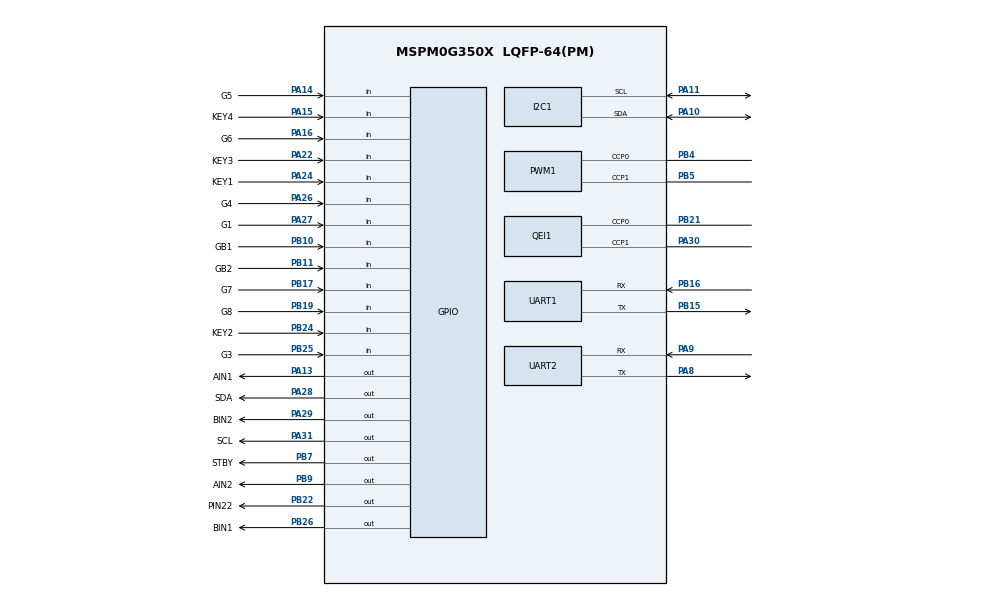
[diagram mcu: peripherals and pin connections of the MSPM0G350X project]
/**
 * @cliArgs --device "MSPM0G350X" --part "Default" --package "LQFP-64(PM)" --product "mspm0_sdk@2.10.00.04"
 * @versions {"tool":"1.26.2+4477"}
 */

/**
 * Import the modules used in this configuration.
 */
const GPIO    = scripting.addModule("/ti/driverlib/GPIO", {}, false);
const GPIO1   = GPIO.addInstance();
const GPIO2   = GPIO.addInstance();
const GPIO3   = GPIO.addInstance();
const GPIO4   = GPIO.addInstance();
const GPIO5   = GPIO.addInstance();
const I2C     = scripting.addModule("/ti/driverlib/I2C", {}, false);
const I2C1    = I2C.addInstance();
const PWM     = scripting.addModule("/ti/driverlib/PWM", {}, false);
const PWM1    = PWM.addInstance();
const QEI     = scripting.addModule("/ti/driverlib/QEI", {}, false);
const QEI1    = QEI.addInstance();
const SYSCTL  = scripting.addModule("/ti/driverlib/SYSCTL");
const SYSTICK = scripting.addModule("/ti/driverlib/SYSTICK");
const TIMER   = scripting.addModule("/ti/driverlib/TIMER", {}, false);
const TIMER1  = TIMER.addInstance();
const TIMER2  = TIMER.addInstance();
const TIMER3  = TIMER.addInstance();
const TIMER4  = TIMER.addInstance();
const UART    = scripting.addModule("/ti/driverlib/UART", {}, false);
const UART1   = UART.addInstance();
const UART2   = UART.addInstance();

/**
 * Write custom configuration values to the imported modules.
 */
GPIO1.$name                               = "Motor";
GPIO1.associatedPins.create(7);
GPIO1.associatedPins[0].$name             = "AIN1";
GPIO1.associatedPins[0].assignedPin       = "13";
GPIO1.associatedPins[0].pin.$assign       = "PA13";
GPIO1.associatedPins[1].$name             = "AIN2";
GPIO1.associatedPins[1].assignedPin       = "9";
GPIO1.associatedPins[1].pin.$assign       = "PB9";
GPIO1.associatedPins[2].$name             = "BIN1";
GPIO1.associatedPins[2].assignedPin       = "26";
GPIO1.associatedPins[2].pin.$assign       = "PB26";
GPIO1.associatedPins[3].$name             = "BIN2";
GPIO1.associatedPins[3].assignedPin       = "29";
GPIO1.associatedPins[3].pin.$assign       = "PA29";
GPIO1.associatedPins[4].$name             = "STBY";
GPIO1.associatedPins[4].assignedPin       = "07";
GPIO1.associatedPins[4].pin.$assign       = "PB7";
GPIO1.associatedPins[5].$name             = "GB1";
GPIO1.associatedPins[5].direction         = "INPUT";
GPIO1.associatedPins[5].internalResistor  = "PULL_DOWN";
GPIO1.associatedPins[5].assignedPin       = "10";
GPIO1.associatedPins[5].interruptEn       = true;
GPIO1.associatedPins[5].interruptPriority = "1";
GPIO1.associatedPins[5].pubChanID         = 1;
GPIO1.associatedPins[5].polarity          = "RISE";
GPIO1.associatedPins[5].pin.$assign       = "PB10";
GPIO1.associatedPins[6].$name             = "GB2";
GPIO1.associatedPins[6].direction         = "INPUT";
GPIO1.associatedPins[6].inputFilter       = "1_CYCLE";
GPIO1.associatedPins[6].assignedPin       = "11";
GPIO1.associatedPins[6].internalResistor  = "PULL_UP";
GPIO1.associatedPins[6].pin.$assign       = "PB11";

const Board = scripting.addModule("/ti/driverlib/Board", {}, false);

GPIO2.$name                         = "LED";
GPIO2.associatedPins[0].$name       = "PIN22";
GPIO2.associatedPins[0].assignedPin = "22";
GPIO2.associatedPins[0].pin.$assign = "PB22";

GPIO3.$name                              = "KEY";
GPIO3.associatedPins.create(4);
GPIO3.associatedPins[0].direction        = "INPUT";
GPIO3.associatedPins[0].$name            = "KEY1";
GPIO3.associatedPins[0].internalResistor = "PULL_UP";
GPIO3.associatedPins[0].assignedPin      = "24";
GPIO3.associatedPins[0].pin.$assign      = "PA24";
GPIO3.associatedPins[1].$name            = "KEY2";
GPIO3.associatedPins[1].direction        = "INPUT";
GPIO3.associatedPins[1].internalResistor = "PULL_UP";
GPIO3.associatedPins[1].assignedPin      = "24";
GPIO3.associatedPins[1].pin.$assign      = "PB24";
GPIO3.associatedPins[2].$name            = "KEY3";
GPIO3.associatedPins[2].direction        = "INPUT";
GPIO3.associatedPins[2].internalResistor = "PULL_UP";
GPIO3.associatedPins[2].assignedPin      = "22";
GPIO3.associatedPins[2].pin.$assign      = "PA22";
GPIO3.associatedPins[3].$name            = "KEY4";
GPIO3.associatedPins[3].direction        = "INPUT";
GPIO3.associatedPins[3].internalResistor = "PULL_UP";
GPIO3.associatedPins[3].assignedPin      = "15";
GPIO3.associatedPins[3].pin.$assign      = "PA15";

GPIO4.$name                         = "XG";
GPIO4.associatedPins.create(8);
GPIO4.associatedPins[0].direction   = "INPUT";
GPIO4.associatedPins[0].$name       = "G1";
GPIO4.associatedPins[0].assignedPin = "27";
GPIO4.associatedPins[0].pin.$assign = "PA27";
GPIO4.associatedPins[1].$name       = "G2";
GPIO4.associatedPins[1].direction   = "INPUT";
GPIO4.associatedPins[1].assignedPin = "25";
GPIO4.associatedPins[2].$name       = "G3";
GPIO4.associatedPins[2].direction   = "INPUT";
GPIO4.associatedPins[2].assignedPin = "25";
GPIO4.associatedPins[2].pin.$assign = "PB25";
GPIO4.associatedPins[3].$name       = "G4";
GPIO4.associatedPins[3].direction   = "INPUT";
GPIO4.associatedPins[3].assignedPin = "26";
GPIO4.associatedPins[3].pin.$assign = "PA26";
GPIO4.associatedPins[4].$name       = "G5";
GPIO4.associatedPins[4].direction   = "INPUT";
GPIO4.associatedPins[4].assignedPin = "14";
GPIO4.associatedPins[4].pin.$assign = "PA14";
GPIO4.associatedPins[5].$name       = "G6";
GPIO4.associatedPins[5].direction   = "INPUT";
GPIO4.associatedPins[5].assignedPin = "16";
GPIO4.associatedPins[5].pin.$assign = "PA16";
GPIO4.associatedPins[6].$name       = "G7";
GPIO4.associatedPins[6].direction   = "INPUT";
GPIO4.associatedPins[6].assignedPin = "17";
GPIO4.associatedPins[6].pin.$assign = "PB17";
GPIO4.associatedPins[7].$name       = "G8";
GPIO4.associatedPins[7].direction   = "INPUT";
GPIO4.associatedPins[7].assignedPin = "19";
GPIO4.associatedPins[7].pin.$assign = "PB19";

GPIO5.$name                          = "I2C";
GPIO5.associatedPins.create(2);
GPIO5.associatedPins[0].$name        = "SCL";
GPIO5.associatedPins[0].assignedPort = "PORTA";
GPIO5.associatedPins[0].assignedPin  = "any";
GPIO5.associatedPins[0].pin.$assign  = "PA31";
GPIO5.associatedPins[1].$name        = "SDA";
GPIO5.associatedPins[1].assignedPin  = "any";
GPIO5.associatedPins[1].pin.$assign  = "PA28";

I2C1.basicEnableController             = true;
I2C1.$name                             = "I2C_1";
I2C1.peripheral.$assign                = "I2C1";
I2C1.peripheral.sdaPin.$assign         = "PA10";
I2C1.peripheral.sclPin.$assign         = "PA11";
I2C1.sdaPinConfig.$name                = "ti_driverlib_gpio_GPIOPinGeneric0";
I2C1.sdaPinConfig.hideOutputInversion  = scripting.forceWrite(false);
I2C1.sdaPinConfig.onlyInternalResistor = scripting.forceWrite(false);
I2C1.sdaPinConfig.passedPeripheralType = scripting.forceWrite("Digital");
I2C1.sclPinConfig.$name                = "ti_driverlib_gpio_GPIOPinGeneric1";
I2C1.sclPinConfig.hideOutputInversion  = scripting.forceWrite(false);
I2C1.sclPinConfig.onlyInternalResistor = scripting.forceWrite(false);
I2C1.sclPinConfig.passedPeripheralType = scripting.forceWrite("Digital");

PWM1.$name                           = "PWM_0";
PWM1.clockPrescale                   = 200;
PWM1.timerStartTimer                 = true;
PWM1.timerCount                      = 99;
PWM1.ccIndexCmpl                     = [0,1];
PWM1.enableShadowLoad                = true;
PWM1.counterLoad                     = true;
PWM1.PWM_CHANNEL_0.$name             = "ti_driverlib_pwm_PWMTimerCC0";
PWM1.PWM_CHANNEL_0.dutyCycle         = 30;
PWM1.PWM_CHANNEL_0.ccValue           = 29;
PWM1.PWM_CHANNEL_1.$name             = "ti_driverlib_pwm_PWMTimerCC1";
PWM1.PWM_CHANNEL_1.dutyCycle         = 30;
PWM1.PWM_CHANNEL_1.ccValue           = 29;
PWM1.ccp0PinConfig.$name             = "ti_driverlib_gpio_GPIOPinGeneric10";
PWM1.ccp0PinConfig.enableConfig      = true;
PWM1.ccp1PinConfig.$name             = "ti_driverlib_gpio_GPIOPinGeneric11";
PWM1.peripheral.$assign              = "TIMA1";
PWM1.peripheral.ccp0Pin.$assign      = "PB4";
PWM1.peripheral.ccp0Pin_cmpl.$assign = "PB6";
PWM1.peripheral.ccp1Pin.$assign      = "PB5";
PWM1.peripheral.ccp1Pin_cmpl.$assign = "PB20";
PWM1.ccp0Pin_cmplConfig.$name        = "ti_driverlib_gpio_GPIOPinGeneric12";
PWM1.ccp1Pin_cmplConfig.$name        = "ti_driverlib_gpio_GPIOPinGeneric13";

QEI1.$name                       = "QEI_0";
QEI1.timerStartTimer             = true;
QEI1.clockDivider                = 5;
QEI1.event1ControllerInterruptEn = ["LOAD_EVENT"];
QEI1.peripheral.$assign          = "TIMG8";
QEI1.peripheral.ccp0Pin.$assign  = "PB21";
QEI1.peripheral.ccp1Pin.$assign  = "PA30";
QEI1.ccp0PinConfig.$name         = "ti_driverlib_gpio_GPIOPinGeneric14";
QEI1.ccp0PinConfig.enableConfig  = true;
QEI1.ccp1PinConfig.$name         = "ti_driverlib_gpio_GPIOPinGeneric15";
QEI1.ccp1PinConfig.enableConfig  = true;

SYSCTL.forceDefaultClkConfig = true;

SYSTICK.interruptPriority = "0";
SYSTICK.systickEnable     = true;
SYSTICK.periodEnable      = true;
SYSTICK.period            = 31999;

TIMER1.$name              = "TIMER_0";
TIMER1.timerClkDiv        = 8;
TIMER1.timerClkPrescale   = 100;
TIMER1.timerMode          = "PERIODIC_UP";
TIMER1.timerStartTimer    = true;
TIMER1.timerPeriod        = "5ms";
TIMER1.peripheral.$assign = "TIMG0";

TIMER2.$name              = "TIMER_GB";
TIMER2.timerClkPrescale   = 200;
TIMER2.timerPeriod        = "10 ms";
TIMER2.enableShadowLoad   = true;
TIMER2.interrupts         = ["LOAD"];
TIMER2.interruptPriority  = "2";
TIMER2.timerMode          = "PERIODIC_UP";
TIMER2.peripheral.$assign = "TIMG6";

TIMER3.$name              = "TIMER_count";
TIMER3.timerMode          = "PERIODIC_UP";
TIMER3.timerClkDiv        = 8;
TIMER3.timerClkPrescale   = 20;
TIMER3.timerStartTimer    = true;
TIMER3.interrupts         = ["LOAD"];
TIMER3.interruptPriority  = "0";
TIMER3.timerPeriod        = "10 ms";
TIMER3.peripheral.$assign = "TIMG7";

TIMER4.$name                  = "TIMER_TICK";
TIMER4.timerClkSrc            = "LFCLK";
TIMER4.timerMode              = "PERIODIC_UP";
TIMER4.timerStartTimer        = true;
TIMER4.timerPeriod            = "1ms";
TIMER4.enableShadowLoad       = true;
TIMER4.interruptPriority      = "0";
TIMER4.event1PublisherChannel = 2;
TIMER4.interrupts             = ["LOAD"];
TIMER4.peripheral.$assign     = "TIMA0";

UART1.$name                            = "UART_XG";
UART1.targetBaudRate                   = 115200;
UART1.peripheral.rxPin.$assign         = "PB16";
UART1.peripheral.txPin.$assign         = "PB15";
UART1.txPinConfig.direction            = scripting.forceWrite("OUTPUT");
UART1.txPinConfig.hideOutputInversion  = scripting.forceWrite(false);
UART1.txPinConfig.onlyInternalResistor = scripting.forceWrite(false);
UART1.txPinConfig.passedPeripheralType = scripting.forceWrite("Digital");
UART1.txPinConfig.$name                = "ti_driverlib_gpio_GPIOPinGeneric4";
UART1.rxPinConfig.hideOutputInversion  = scripting.forceWrite(false);
UART1.rxPinConfig.onlyInternalResistor = scripting.forceWrite(false);
UART1.rxPinConfig.passedPeripheralType = scripting.forceWrite("Digital");
UART1.rxPinConfig.$name                = "ti_driverlib_gpio_GPIOPinGeneric5";

UART2.$name                            = "UART_ICM";
UART2.uartClkDiv                       = "8";
UART2.targetBaudRate                   = 115200;
UART2.peripheral.rxPin.$assign         = "PA9";
UART2.peripheral.txPin.$assign         = "PA8";
UART2.txPinConfig.direction            = scripting.forceWrite("OUTPUT");
UART2.txPinConfig.hideOutputInversion  = scripting.forceWrite(false);
UART2.txPinConfig.onlyInternalResistor = scripting.forceWrite(false);
UART2.txPinConfig.passedPeripheralType = scripting.forceWrite("Digital");
UART2.txPinConfig.$name                = "ti_driverlib_gpio_GPIOPinGeneric6";
UART2.rxPinConfig.hideOutputInversion  = scripting.forceWrite(false);
UART2.rxPinConfig.onlyInternalResistor = scripting.forceWrite(false);
UART2.rxPinConfig.passedPeripheralType = scripting.forceWrite("Digital");
UART2.rxPinConfig.$name                = "ti_driverlib_gpio_GPIOPinGeneric7";

/**
 * Pinmux solution for unlocked pins/peripherals. This ensures that minor changes to the automatic solver in a future
 * version of the tool will not impact the pinmux you originally saw.  These lines can be completely deleted in order to
 * re-solve from scratch.
 */
Board.peripheral.$suggestSolution            = "DEBUGSS";
Board.peripheral.swclkPin.$suggestSolution   = "PA20";
Board.peripheral.swdioPin.$suggestSolution   = "PA19";
GPIO4.associatedPins[1].pin.$suggestSolution = "PA25";
SYSCTL.peripheral.$suggestSolution           = "SYSCTL";
UART1.peripheral.$suggestSolution            = "UART2";
UART2.peripheral.$suggestSolution            = "UART1";
